# TM4C129ENCPDT register map
File version: 1.0
CPU: CORTEX_M4 1.0, other endian, MPU, FPU, 3 interrupt priority bits
Registers are 32-bit, read-write, reset 0x0 unless marked. A register's access mark holds for its fields unless they carry their own. Offsets are from the block's base; [hi:lo] are bit positions; {n}, {i} and the like mark numbered series.

## SYSEXC — System Exception Module register addresses
Base 0x400F9000
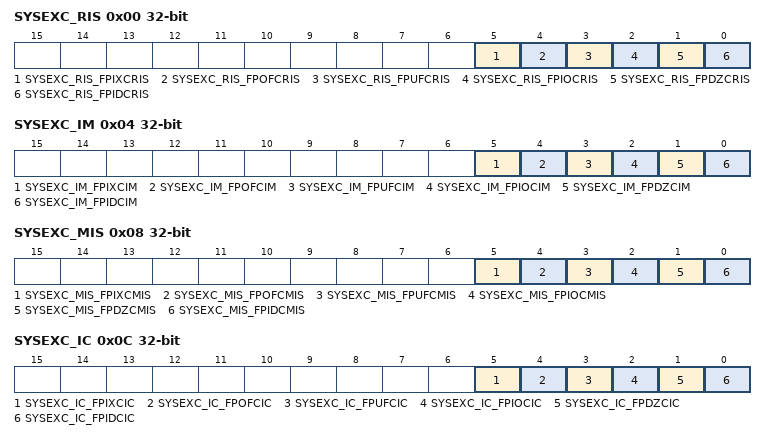
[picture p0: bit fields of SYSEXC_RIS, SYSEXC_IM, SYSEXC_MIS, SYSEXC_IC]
0x00 SYSEXC_RIS — System Exception Raw Interrupt Status
  [5] SYSEXC_RIS_FPIXCRIS — [5:5] Floating-Point Inexact Exception Raw Interrupt Status
  [4] SYSEXC_RIS_FPOFCRIS — [4:4] Floating-Point Overflow Exception Raw Interrupt Status
  [3] SYSEXC_RIS_FPUFCRIS — [3:3] Floating-Point Underflow Exception Raw Interrupt Status
  [2] SYSEXC_RIS_FPIOCRIS — [2:2] Floating-Point Invalid Operation Raw Interrupt Status
  [1] SYSEXC_RIS_FPDZCRIS — [1:1] Floating-Point Divide By 0 Exception Raw Interrupt Status
  [0] SYSEXC_RIS_FPIDCRIS — [0:0] Floating-Point Input Denormal Exception Raw Interrupt Status
0x04 SYSEXC_IM — System Exception Interrupt Mask
  [5] SYSEXC_IM_FPIXCIM — [5:5] Floating-Point Inexact Exception Interrupt Mask
  [4] SYSEXC_IM_FPOFCIM — [4:4] Floating-Point Overflow Exception Interrupt Mask
  [3] SYSEXC_IM_FPUFCIM — [3:3] Floating-Point Underflow Exception Interrupt Mask
  [2] SYSEXC_IM_FPIOCIM — [2:2] Floating-Point Invalid Operation Interrupt Mask
  [1] SYSEXC_IM_FPDZCIM — [1:1] Floating-Point Divide By 0 Exception Interrupt Mask
  [0] SYSEXC_IM_FPIDCIM — [0:0] Floating-Point Input Denormal Exception Interrupt Mask
0x08 SYSEXC_MIS — System Exception Masked Interrupt Status
  [5] SYSEXC_MIS_FPIXCMIS — [5:5] Floating-Point Inexact Exception Masked Interrupt Status
  [4] SYSEXC_MIS_FPOFCMIS — [4:4] Floating-Point Overflow Exception Masked Interrupt Status
  [3] SYSEXC_MIS_FPUFCMIS — [3:3] Floating-Point Underflow Exception Masked Interrupt Status
  [2] SYSEXC_MIS_FPIOCMIS — [2:2] Floating-Point Invalid Operation Masked Interrupt Status
  [1] SYSEXC_MIS_FPDZCMIS — [1:1] Floating-Point Divide By 0 Exception Masked Interrupt Status
  [0] SYSEXC_MIS_FPIDCMIS — [0:0] Floating-Point Input Denormal Exception Masked Interrupt Status
0x0C SYSEXC_IC — System Exception Interrupt Clear
  [5] SYSEXC_IC_FPIXCIC — [5:5] Floating-Point Inexact Exception Interrupt Clear
  [4] SYSEXC_IC_FPOFCIC — [4:4] Floating-Point Overflow Exception Interrupt Clear
  [3] SYSEXC_IC_FPUFCIC — [3:3] Floating-Point Underflow Exception Interrupt Clear
  [2] SYSEXC_IC_FPIOCIC — [2:2] Floating-Point Invalid Operation Interrupt Clear
  [1] SYSEXC_IC_FPDZCIC — [1:1] Floating-Point Divide By 0 Exception Interrupt Clear
  [0] SYSEXC_IC_FPIDCIC — [0:0] Floating-Point Input Denormal Exception Interrupt Clear

## UDMA — Micro Direct Memory Access register addresses
Base 0x400FF000
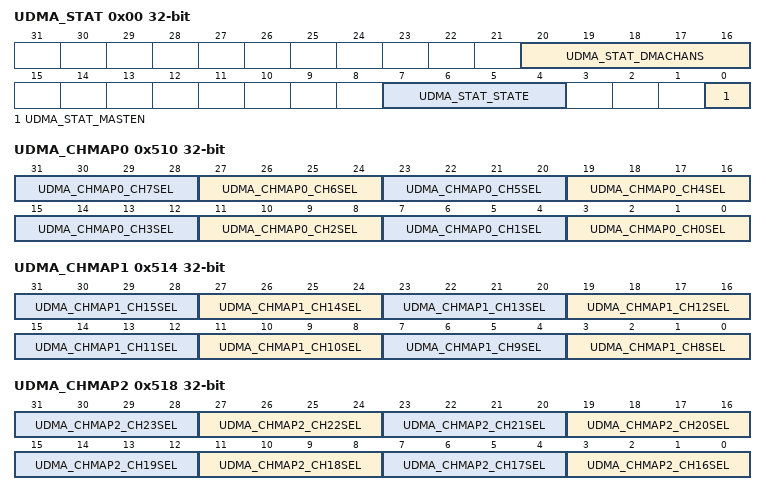
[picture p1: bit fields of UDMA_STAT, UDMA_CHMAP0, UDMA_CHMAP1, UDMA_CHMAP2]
0x00 UDMA_STAT — DMA Status
  [20:16] UDMA_STAT_DMACHANS — [20:16] Available uDMA Channels Minus 1
  [7:4] UDMA_STAT_STATE — [7:4] Control State Machine Status
    0=UDMA_STAT_STATE_IDLE (Idle); 16=UDMA_STAT_STATE_RD_CTRL (Reading channel controller data); 32=UDMA_STAT_STATE_RD_SRCENDP (Reading source end pointer); 48=UDMA_STAT_STATE_RD_DSTENDP (Reading destination end pointer); 64=UDMA_STAT_STATE_RD_SRCDAT (Reading source data); 80=UDMA_STAT_STATE_WR_DSTDAT (Writing destination data); 96=UDMA_STAT_STATE_WAIT (Waiting for uDMA request to clear); 112=UDMA_STAT_STATE_WR_CTRL (Writing channel controller data); 128=UDMA_STAT_STATE_STALL (Stalled); 144=UDMA_STAT_STATE_DONE (Done); 160=UDMA_STAT_STATE_UNDEF (Undefined)
  [0] UDMA_STAT_MASTEN — [0:0] Master Enable Status
0x04 UDMA_CFG — DMA Configuration
  [0] UDMA_CFG_MASTEN — [0:0] Controller Master Enable
0x08 UDMA_CTLBASE — DMA Channel Control Base Pointer
  [31:10] UDMA_CTLBASE_ADDR — [31:10] Channel Control Base Address
0x0C UDMA_ALTBASE — DMA Alternate Channel Control Base Pointer
  [31:0] UDMA_ALTBASE_ADDR — [31:0] Alternate Channel Address Pointer
0x10 UDMA_WAITSTAT — DMA Channel Wait-on-Request Status
  [31:0] UDMA_WAITSTAT_WAITREQ — [31:0] Channel [n] Wait Status
0x14 UDMA_SWREQ — DMA Channel Software Request
  [31:0] UDMA_SWREQ — [31:0] Channel [n] Software Request
0x18 UDMA_USEBURSTSET — DMA Channel Useburst Set
  [31:0] UDMA_USEBURSTSET_SET — [31:0] Channel [n] Useburst Set
0x1C UDMA_USEBURSTCLR — DMA Channel Useburst Clear
  [31:0] UDMA_USEBURSTCLR_CLR — [31:0] Channel [n] Useburst Clear
0x20 UDMA_REQMASKSET — DMA Channel Request Mask Set
  [31:0] UDMA_REQMASKSET_SET — [31:0] Channel [n] Request Mask Set
0x24 UDMA_REQMASKCLR — DMA Channel Request Mask Clear
  [31:0] UDMA_REQMASKCLR_CLR — [31:0] Channel [n] Request Mask Clear
0x28 UDMA_ENASET — DMA Channel Enable Set
  [31:0] UDMA_ENASET_SET — [31:0] Channel [n] Enable Set
0x2C UDMA_ENACLR — DMA Channel Enable Clear
  [31:0] UDMA_ENACLR_CLR — [31:0] Clear Channel [n] Enable Clear
0x30 UDMA_ALTSET — DMA Channel Primary Alternate Set
  [31:0] UDMA_ALTSET_SET — [31:0] Channel [n] Alternate Set
0x34 UDMA_ALTCLR — DMA Channel Primary Alternate Clear
  [31:0] UDMA_ALTCLR_CLR — [31:0] Channel [n] Alternate Clear
0x38 UDMA_PRIOSET — DMA Channel Priority Set
  [31:0] UDMA_PRIOSET_SET — [31:0] Channel [n] Priority Set
0x3C UDMA_PRIOCLR — DMA Channel Priority Clear
  [31:0] UDMA_PRIOCLR_CLR — [31:0] Channel [n] Priority Clear
0x4C UDMA_ERRCLR — DMA Bus Error Clear
  [0] UDMA_ERRCLR_ERRCLR — [0:0] uDMA Bus Error Status
0x500 UDMA_CHASGN — DMA Channel Assignment
  [31:0] UDMA_CHASGN — [31:0] Channel [n] Assignment Select
    0=UDMA_CHASGN_PRIMARY (Use the primary channel assignment); 1=UDMA_CHASGN_SECONDARY (Use the secondary channel assignment)
0x510 UDMA_CHMAP0 — DMA Channel Map Select 0
  [4n+3:4n] UDMA_CHMAP0_CH{n}SEL (n=0..7) — [{4n+3}:{4n}] uDMA Channel {n} Source Select
0x514 UDMA_CHMAP1 — DMA Channel Map Select 1
  [4n-29:4n-32] UDMA_CHMAP1_CH{n}SEL (n=8..15) — [{4n-29}:{4n-32}] uDMA Channel {n} Source Select
0x518 UDMA_CHMAP2 — DMA Channel Map Select 2
  [4n-61:4n-64] UDMA_CHMAP2_CH{n}SEL (n=16..23) — [{4n-61}:{4n-64}] uDMA Channel {n} Source Select
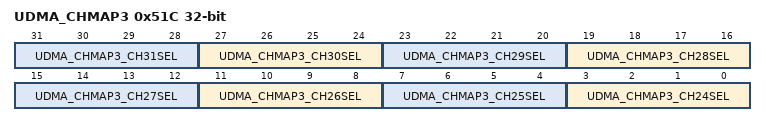
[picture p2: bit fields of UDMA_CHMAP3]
0x51C UDMA_CHMAP3 — DMA Channel Map Select 3
  [4n-93:4n-96] UDMA_CHMAP3_CH{n}SEL (n=24..31) — [{4n-93}:{4n-96}] uDMA Channel {n} Source Select

## CCM0 — EC register offsets
Base 0x44030000
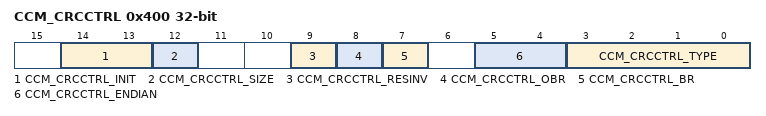
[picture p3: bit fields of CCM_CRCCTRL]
0x400 CCM_CRCCTRL — CRC Control
  [14:13] CCM_CRCCTRL_INIT — [14:13] CRC Initialization
    0=CCM_CRCCTRL_INIT_SEED (Use the CRCSEED register context as the starting value); 0x4000=Initialize to all '0s'; 0x6000=Initialize to all '1s'
  [12] CCM_CRCCTRL_SIZE — [12:12] Input Data Size
  [9] CCM_CRCCTRL_RESINV — [9:9] Result Inverse Enable
  [8] CCM_CRCCTRL_OBR — [8:8] Output Reverse Enable
  [7] CCM_CRCCTRL_BR — [7:7] Bit reverse enable
  [5:4] CCM_CRCCTRL_ENDIAN — [5:4] Endian Control
    0=CCM_CRCCTRL_ENDIAN_SBHW (Configuration unchanged. (B3, B2, B1, B0)); 16=CCM_CRCCTRL_ENDIAN_SHW (Bytes are swapped in half-words but half-words are not swapped (B2, B3, B0, B1)); 32=CCM_CRCCTRL_ENDIAN_SHWNB (Half-words are swapped but bytes are not swapped in half-word. (B1, B0, B3, B2)); 48=CCM_CRCCTRL_ENDIAN_SBSW (Bytes are swapped in half-words and half-words are swapped. (B0, B1, B2, B3))
  [3:0] CCM_CRCCTRL_TYPE — [3:0] Operation Type
    0=CCM_CRCCTRL_TYPE_P8055 (Polynomial 0x8005); 1=CCM_CRCCTRL_TYPE_P1021 (Polynomial 0x1021); 2=CCM_CRCCTRL_TYPE_P4C11DB7 (Polynomial 0x4C11DB7); 3=CCM_CRCCTRL_TYPE_P1EDC6F41 (Polynomial 0x1EDC6F41); 8=CCM_CRCCTRL_TYPE_TCPCHKSUM (TCP checksum)
0x410 CCM_CRCSEED — CRC SEED/Context
  [31:0] CCM_CRCSEED_SEED — [31:0] SEED/Context Value
0x414 CCM_CRCDIN — CRC Data Input
  [31:0] CCM_CRCDIN_DATAIN — [31:0] Data Input
0x418 CCM_CRCRSLTPP — CRC Post Processing Result
  [31:0] CCM_CRCRSLTPP_RSLTPP — [31:0] Post Processing Result
